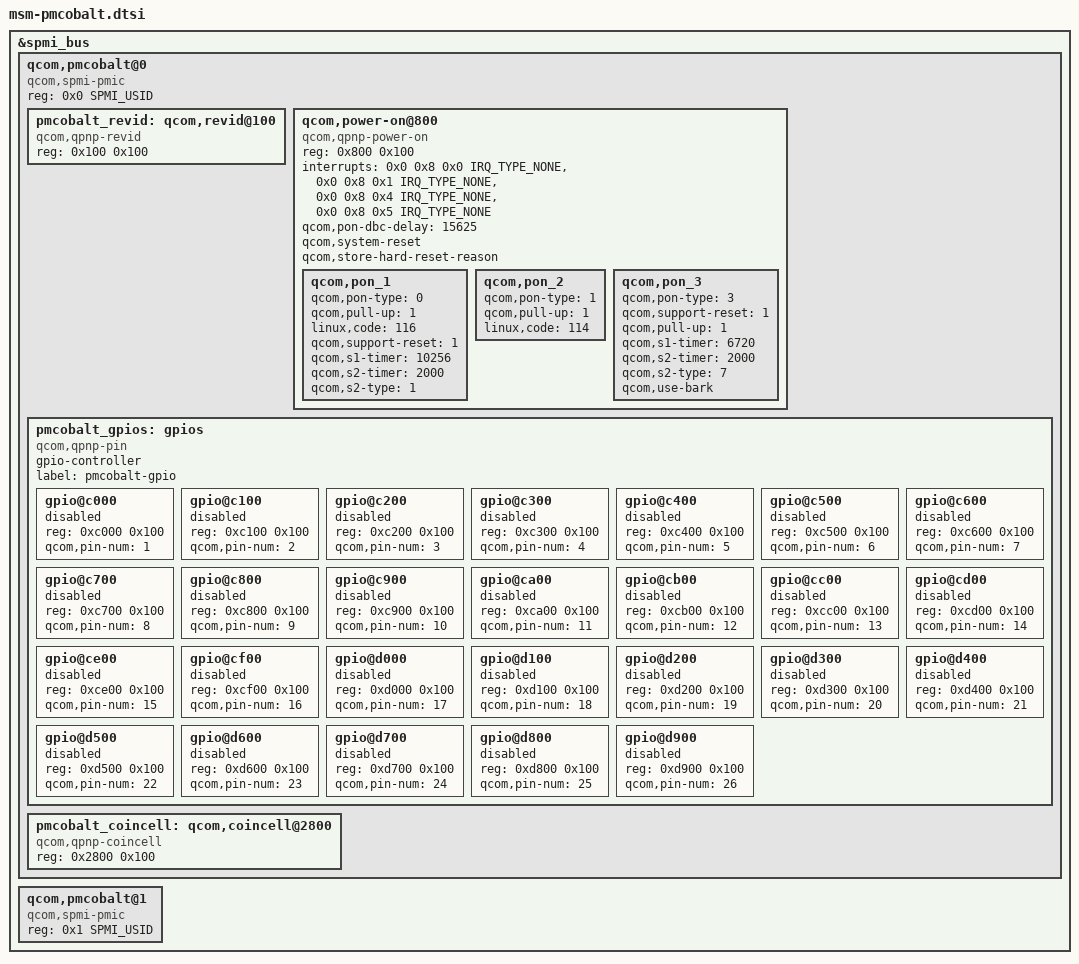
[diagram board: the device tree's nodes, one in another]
/* Copyright (c) 2016, The Linux Foundation. All rights reserved.
 *
 * This program is free software; you can redistribute it and/or modify
 * it under the terms of the GNU General Public License version 2 and
 * only version 2 as published by the Free Software Foundation.
 *
 * This program is distributed in the hope that it will be useful,
 * but WITHOUT ANY WARRANTY; without even the implied warranty of
 * MERCHANTABILITY or FITNESS FOR A PARTICULAR PURPOSE.  See the
 * GNU General Public License for more details.
 */

#include <dt-bindings/spmi/spmi.h>
#include <dt-bindings/interrupt-controller/irq.h>

&spmi_bus {
	qcom,pmcobalt@0 {
		compatible ="qcom,spmi-pmic";
		reg = <0x0 SPMI_USID>;
		#address-cells = <2>;
		#size-cells = <0>;

		pmcobalt_revid: qcom,revid@100 {
			compatible = "qcom,qpnp-revid";
			reg = <0x100 0x100>;
		};

		qcom,power-on@800 {
			compatible = "qcom,qpnp-power-on";
			reg = <0x800 0x100>;
			interrupts = <0x0 0x8 0x0 IRQ_TYPE_NONE>,
				     <0x0 0x8 0x1 IRQ_TYPE_NONE>,
				     <0x0 0x8 0x4 IRQ_TYPE_NONE>,
				     <0x0 0x8 0x5 IRQ_TYPE_NONE>;
			interrupt-names = "kpdpwr", "resin",
					"resin-bark", "kpdpwr-resin-bark";
			qcom,pon-dbc-delay = <15625>;
			qcom,system-reset;
			qcom,store-hard-reset-reason;

			qcom,pon_1 {
				qcom,pon-type = <0>;
				qcom,pull-up = <1>;
				linux,code = <116>;
				qcom,support-reset = <1>;
				qcom,s1-timer = <10256>;
				qcom,s2-timer = <2000>;
				qcom,s2-type = <1>;
			};

			qcom,pon_2 {
				qcom,pon-type = <1>;
				qcom,pull-up = <1>;
				linux,code = <114>;
			};

			qcom,pon_3 {
				qcom,pon-type = <3>;
				qcom,support-reset = <1>;
				qcom,pull-up = <1>;
				qcom,s1-timer = <6720>;
				qcom,s2-timer = <2000>;
				qcom,s2-type = <7>;
				qcom,use-bark;
			};
		};

		pmcobalt_gpios: gpios {
			compatible = "qcom,qpnp-pin";
			gpio-controller;
			#gpio-cells = <2>;
			#address-cells = <1>;
			#size-cells = <1>;
			label = "pmcobalt-gpio";

			gpio@c000 {
				reg = <0xc000 0x100>;
				qcom,pin-num = <1>;
				status = "disabled";
			};

			gpio@c100 {
				reg = <0xc100 0x100>;
				qcom,pin-num = <2>;
				status = "disabled";
			};

			gpio@c200 {
				reg = <0xc200 0x100>;
				qcom,pin-num = <3>;
				status = "disabled";
			};

			gpio@c300 {
				reg = <0xc300 0x100>;
				qcom,pin-num = <4>;
				status = "disabled";
			};

			gpio@c400 {
				reg = <0xc400 0x100>;
				qcom,pin-num = <5>;
				status = "disabled";
			};

			gpio@c500 {
				reg = <0xc500 0x100>;
				qcom,pin-num = <6>;
				status = "disabled";
			};

			gpio@c600 {
				reg = <0xc600 0x100>;
				qcom,pin-num = <7>;
				status = "disabled";
			};

			gpio@c700 {
				reg = <0xc700 0x100>;
				qcom,pin-num = <8>;
				status = "disabled";
			};

			gpio@c800 {
				reg = <0xc800 0x100>;
				qcom,pin-num = <9>;
				status = "disabled";
			};

			gpio@c900 {
				reg = <0xc900 0x100>;
				qcom,pin-num = <10>;
				status = "disabled";
			};

			gpio@ca00 {
				reg = <0xca00 0x100>;
				qcom,pin-num = <11>;
				status = "disabled";
			};

			gpio@cb00 {
				reg = <0xcb00 0x100>;
				qcom,pin-num = <12>;
				status = "disabled";
			};

			gpio@cc00 {
				reg = <0xcc00 0x100>;
				qcom,pin-num = <13>;
				status = "disabled";
			};

			gpio@cd00 {
				reg = <0xcd00 0x100>;
				qcom,pin-num = <14>;
				status = "disabled";
			};

			gpio@ce00 {
				reg = <0xce00 0x100>;
				qcom,pin-num = <15>;
				status = "disabled";
			};

			gpio@cf00 {
				reg = <0xcf00 0x100>;
				qcom,pin-num = <16>;
				status = "disabled";
			};

			gpio@d000 {
				reg = <0xd000 0x100>;
				qcom,pin-num = <17>;
				status = "disabled";
			};

			gpio@d100 {
				reg = <0xd100 0x100>;
				qcom,pin-num = <18>;
				status = "disabled";
			};

			gpio@d200 {
				reg = <0xd200 0x100>;
				qcom,pin-num = <19>;
				status = "disabled";
			};

			gpio@d300 {
				reg = <0xd300 0x100>;
				qcom,pin-num = <20>;
				status = "disabled";
			};

			gpio@d400 {
				reg = <0xd400 0x100>;
				qcom,pin-num = <21>;
				status = "disabled";
			};

			gpio@d500 {
				reg = <0xd500 0x100>;
				qcom,pin-num = <22>;
				status = "disabled";
			};

			gpio@d600 {
				reg = <0xd600 0x100>;
				qcom,pin-num = <23>;
				status = "disabled";
			};

			gpio@d700 {
				reg = <0xd700 0x100>;
				qcom,pin-num = <24>;
				status = "disabled";
			};

			gpio@d800 {
				reg = <0xd800 0x100>;
				qcom,pin-num = <25>;
				status = "disabled";
			};

			gpio@d900 {
				reg = <0xd900 0x100>;
				qcom,pin-num = <26>;
				status = "disabled";
			};
		};

		pmcobalt_coincell: qcom,coincell@2800 {
			compatible = "qcom,qpnp-coincell";
			reg = <0x2800 0x100>;
		};
	};

	qcom,pmcobalt@1 {
		compatible ="qcom,spmi-pmic";
		reg = <0x1 SPMI_USID>;
		#address-cells = <2>;
		#size-cells = <0>;
	};
};
